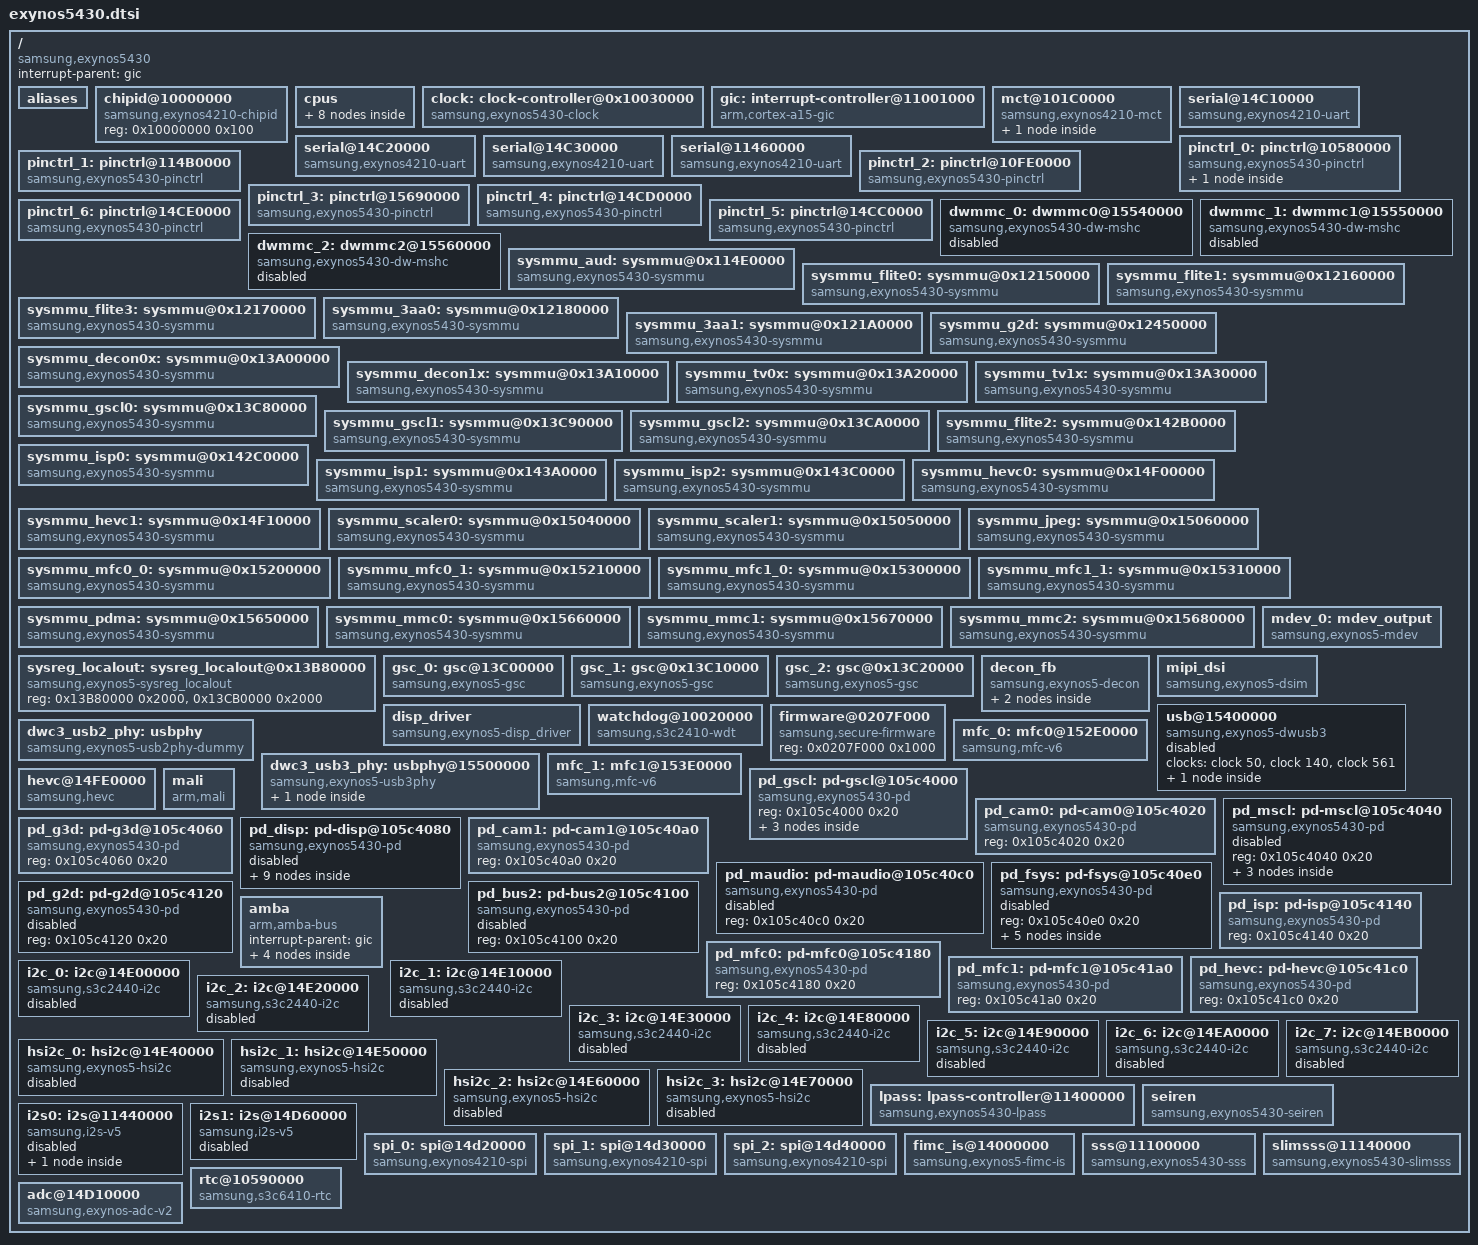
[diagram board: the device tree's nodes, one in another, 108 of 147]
/*
 * SAMSUNG EXYNOS5430 SoC device tree source
 *
 * Copyright (c) 2013 Samsung Electronics Co., Ltd.
 *		http://www.samsung.com
 *
 * SAMSUNG EXYNOS5430 SoC device nodes are listed in this file.
 * EXYNOS5430 based board files can include this file and provide
 * values for board specfic bindings.
 *
 * This program is free software; you can redistribute it and/or modify
 * it under the terms of the GNU General Public License version 2 as
 * published by the Free Software Foundation.
 */

#include "skeleton.dtsi"
/include/ "exynos5430-pinctrl.dtsi"
/ {
	compatible = "samsung,exynos5430";

	interrupt-parent = <&gic>;

	aliases {
		pinctrl0 = &pinctrl_0;
		pinctrl1 = &pinctrl_1;
		pinctrl2 = &pinctrl_2;
		pinctrl3 = &pinctrl_3;
		pinctrl4 = &pinctrl_4;
		pinctrl5 = &pinctrl_5;
		pinctrl6 = &pinctrl_6;
		mshc0 = &dwmmc_0;
		mshc1 = &dwmmc_1;
		mshc2 = &dwmmc_2;
		gsc0 = &gsc_0;
		gsc1 = &gsc_1;
		gsc2 = &gsc_2;
		mfc0 = &mfc_0;
		mfc1 = &mfc_1;
		mdev0 = &mdev_0;
		spi0 = &spi_0;
		spi1 = &spi_1;
		spi2 = &spi_2;
	};

	chipid@10000000 {
		compatible = "samsung,exynos4210-chipid";
		reg = <0x10000000 0x100>;
	};

	cpus {
		#address-cells = <1>;
		#size-cells = <0>;

		cpu@0 {
			device_type = "cpu";
			compatible = "arm,cortex-a7";
			reg = <0x100>;
		};
		cpu@1 {
			device_type = "cpu";
			compatible = "arm,cortex-a7";
			reg = <0x101>;
		};
		cpu@2 {
			device_type = "cpu";
			compatible = "arm,cortex-a7";
			reg = <0x102>;
		};
		cpu@3 {
			device_type = "cpu";
			compatible = "arm,cortex-a7";
			reg = <0x103>;
		};
		cpu@4 {
			device_type = "cpu";
			compatible = "arm,cortex-a15";
			reg = <0x0>;
		};
		cpu@5 {
			device_type = "cpu";
			compatible = "arm,cortex-a15";
			reg = <0x1>;
		};
		cpu@6 {
			device_type = "cpu";
			compatible = "arm,cortex-a15";
			reg = <0x2>;
		};
		cpu@7 {
			device_type = "cpu";
			compatible = "arm,cortex-a15";
			reg = <0x3>;
		};
	};

	clock: clock-controller@0x10030000 {
		compatible = "samsung,exynos5430-clock";
		reg = <0x10030000 0x1000>,
			<0x11800000 0x1000>,
			<0x11900000 0x1000>,
			<0x114C0000 0x1000>,
			<0x14800000 0x1000>,
			<0x13400000 0x1000>,
			<0x120D0000 0x1000>,
			<0x121C0000 0x1000>,
			<0x145D0000 0x1000>,
			<0x142F0000 0x1000>,
			<0x10FC0000 0x1000>,
			<0x13B90000 0x1000>,
			<0x156E0000 0x1000>,
			<0x12460000 0x1000>,
			<0x14AA0000 0x1000>,
			<0x13CF0000 0x1000>,
			<0x14F80000 0x1000>,
			<0x11060000 0x1000>,
			<0x146D0000 0x1000>,
			<0x14360000 0x1000>,
			<0x15280000 0x1000>,
			<0x15380000 0x1000>,
			<0x105B0000 0x1000>,
			<0x150D0000 0x1000>,
			<0x14C80000 0x1000>,
			<0x10040000 0x1000>;
		#clock-cells = <1>;
	};

	gic:interrupt-controller@11001000 {
		compatible = "arm,cortex-a15-gic";
		#interrupt-cells = <3>;
		interrupt-controller;
		reg =	<0x11001000 0x1000>,
			<0x11002000 0x1000>,
			<0x11004000 0x2000>,
			<0x11006000 0x2000>;
		interrupts = <1 9 0xf04>;
	};

	mct@101C0000 {
		compatible = "samsung,exynos4210-mct";
		reg = <0x101C0000 0x800>;
		interrupt-controller;
		#interrups-cells = <1>;
		interrupt-parent = <&mct_map>;
		interrupts =	<0>, <1>, <2>, <3>,
				<4>, <5>, <6>, <7>,
				<8>, <9>, <10>, <11>;
		clocks = <&clock 1>, <&clock 14>;
		clock-names = "fin_pll", "mct";

		mct_map: mct-map {
			#interrupt-cells = <1>;
			#address-cells = <0>;
			#size-cells = <0>;
			interrupt-map = <0 &gic 0 102 0>,
					<1 &gic 0 103 0>,
					<2 &gic 0 104 0>,
					<3 &gic 0 105 0>,
					<4 &gic 0 106 0>,
					<5 &gic 0 107 0>,
					<6 &gic 0 108 0>,
					<7 &gic 0 109 0>,
					<8 &gic 0 110 0>,
					<9 &gic 0 111 0>,
					<10 &gic 0 112 0>,
					<11 &gic 0 113 0>;
		};
	};

	serial@14C10000 {
		compatible = "samsung,exynos4210-uart";
		reg = <0x14C10000 0x100>;
		interrupts = <0 421 0>;
		pinctrl-names = "default";
		pinctrl-0 = <&uart0_bus>;
		clocks = <&clock 115>, <&clock 2437>;
		clock-names = "sclk_uart0", "gate_uart0";
	};

	serial@14C20000 {
		compatible = "samsung,exynos4210-uart";
		reg = <0x14C20000 0x100>;
		interrupts = <0 422 0>;
		pinctrl-names = "default";
		pinctrl-0 = <&uart1_bus>;
		clocks = <&clock 116>, <&clock 2436>;
		clock-names = "sclk_uart1", "gate_uart1";
	};

	serial@14C30000 {
		compatible = "samsung,exynos4210-uart";
		reg = <0x14C30000 0x100>;
		interrupts = <0 423 0>;
		pinctrl-names = "default";
		pinctrl-0 = <&uart2_bus>;
		clocks = <&clock 117>, <&clock 2435>;
		clock-names = "sclk_uart2", "gate_uart2";
	};

	serial@11460000 {
		compatible = "samsung,exynos4210-uart";
		reg = <0x11460000 0x100>;
		interrupts = <0 67 0>;
		pinctrl-names = "default";
		pinctrl-0 = <&uart_aud_bus>;
		clocks = <&clock 4156>, <&clock 2004>;
		clock-names = "sclk_uart3", "gate_uart3";
	};

	pinctrl_0: pinctrl@10580000 {
		compatible = "samsung,exynos5430-pinctrl";
		reg = <0x10580000 0x1000>;
		interrupts = <0 16 0>;

		wakeup-interrupt-controller {
			compatible = "samsung,exynos4210-wakeup-eint";
			interrupt-parent = <&gic>;
			interrupts = <0 16 0>;
		};
	};

	pinctrl_1: pinctrl@114B0000 {
		compatible = "samsung,exynos5430-pinctrl";
		reg = <0x114B0000 0x1000>;
		interrupts = <0 68 0>;
	};

	pinctrl_2: pinctrl@10FE0000 {
		compatible = "samsung,exynos5430-pinctrl";
		reg = <0x10FE0000 0x1000>;
		interrupts = <0 179 0>;
	};

	pinctrl_3: pinctrl@15690000 {
		compatible = "samsung,exynos5430-pinctrl";
		reg = <0x15690000 0x1000>;
		interrupts = <0 229 0>;
	};

	pinctrl_4: pinctrl@14CD0000 {
		compatible = "samsung,exynos5430-pinctrl";
		reg = <0x14CD0000 0x1100>;
		interrupts = <0 441 0>;
	};

	pinctrl_5: pinctrl@14CC0000 {
		compatible = "samsung,exynos5430-pinctrl";
		reg = <0x14CC0000 0x1100>;
		interrupts = <0 440 0>;
	};

	pinctrl_6: pinctrl@14CE0000 {
		compatible = "samsung,exynos5430-pinctrl";
		reg = <0x14CE0000 0x1100>;
		interrupts = <0 442 0>;
	};

	dwmmc_0: dwmmc0@15540000 {
		compatible = "samsung,exynos5430-dw-mshc";
		reg = <0x15540000 0x2000>;
		interrupts = <0 225 0>;
		#address-cells = <1>;
		#size-cells = <0>;
		clocks = <&clock 565>, <&clock 141>;
		clock-names = "biu", "ciu";
		status = "disabled";
	};

	dwmmc_1: dwmmc1@15550000 {
		compatible = "samsung,exynos5430-dw-mshc";
		reg = <0x15550000 0x2000>;
		interrupts = <0 226 0>;
		#address-cells = <1>;
		#size-cells = <0>;
		clocks = <&clock 566>, <&clock 142>;
		clock-names = "biu", "ciu";
		status = "disabled";
	};

	dwmmc_2: dwmmc2@15560000 {
		compatible = "samsung,exynos5430-dw-mshc";
		reg = <0x15560000 0x2000>;
		interrupts = <0 227 0>;
		#address-cells = <1>;
		#size-cells = <0>;
		clocks = <&clock 567>, <&clock 143>;
		clock-names = "biu", "ciu";
		status = "disabled";
	};

	sysmmu_aud: sysmmu@0x114E0000 {
		compatible = "samsung,exynos5430-sysmmu";
		reg = <0x114E0000 0x1000>;
		interrupts = <0 64 0>;
		status = "ok";
	};

	sysmmu_flite0: sysmmu@0x12150000 {
		compatible = "samsung,exynos5430-sysmmu";
		reg = <0x12150000 0x1000>;
		interrupts = <0 128 0>;
		samsung,power-domain = <&pd_cam0>;
		status = "ok";
	};

	sysmmu_flite1: sysmmu@0x12160000 {
		compatible = "samsung,exynos5430-sysmmu";
		reg = <0x12160000 0x1000>;
		interrupts = <0 130 0>;
		samsung,power-domain = <&pd_cam0>;
		status = "ok";
	};

	sysmmu_flite3: sysmmu@0x12170000 {
		compatible = "samsung,exynos5430-sysmmu";
		reg = <0x12170000 0x1000>;
		interrupts = <0 132 0>;
		samsung,power-domain = <&pd_cam0>;
		status = "ok";
	};

	sysmmu_3aa0: sysmmu@0x12180000 {
		compatible = "samsung,exynos5430-sysmmu";
		reg = <0x12180000 0x1000>;
		interrupts = <0 137 0>;
		samsung,power-domain = <&pd_cam0>;
		status = "ok";
	};

	sysmmu_3aa1: sysmmu@0x121A0000 {
		compatible = "samsung,exynos5430-sysmmu";
		reg = <0x121A0000 0x1000>;
		interrupts = <0 147 0>;
		samsung,power-domain = <&pd_cam0>;
		status = "ok";
	};

	sysmmu_g2d: sysmmu@0x12450000 {
		compatible = "samsung,exynos5430-sysmmu";
		reg = <0x12450000 0x1000>;
		interrupts = <0 257 0>;
		clock-names = "sysmmu", "master";
		clocks = <&clock 457>, <&clock 450>;
		status = "ok";
	};

	sysmmu_decon0x: sysmmu@0x13A00000 {
		compatible = "samsung,exynos5430-sysmmu";
		reg = <0x13A00000 0x1000>;
		interrupts = <0 192 0>;
		clock-names = "sysmmu", "master";
		clocks = <&clock 624>, <&clock 610>;
		status = "ok";
		samsung,power-domain = <&spd_decon>;
	};

	sysmmu_decon1x: sysmmu@0x13A10000 {
		compatible = "samsung,exynos5430-sysmmu";
		reg = <0x13A10000 0x1000>;
		interrupts = <0 194 0>;
		clock-names = "sysmmu", "master";
		clocks = <&clock 625>, <&clock 610>;
		status = "ok";
		samsung,power-domain = <&spd_decon>;
	};

	sysmmu_tv0x: sysmmu@0x13A20000 {
		compatible = "samsung,exynos5430-sysmmu";
		reg = <0x13A20000 0x1000>;
		interrupts = <0 214 0>;
		clock-names = "sysmmu", "master";
		clocks = <&clock 672>, <&clock 665>;
		status = "ok";
	};

	sysmmu_tv1x: sysmmu@0x13A30000 {
		compatible = "samsung,exynos5430-sysmmu";
		reg = <0x13A30000 0x1000>;
		interrupts = <0 216 0>;
		status = "ok";
	};

	sysmmu_gscl0: sysmmu@0x13C80000 {
		compatible = "samsung,exynos5430-sysmmu";
		reg = <0x13C80000 0x1000>;
		interrupts = <0 288 0>;
		clock-names = "sysmmu", "master";
		clocks = <&clock 490>, <&clock 480>;
		status = "ok";
		samsung,power-domain = <&spd_gscl0>;
	};

	sysmmu_gscl1: sysmmu@0x13C90000 {
		compatible = "samsung,exynos5430-sysmmu";
		reg = <0x13C90000 0x1000>;
		interrupts = <0 290 0>;
		clock-names = "sysmmu", "master";
		clocks = <&clock 491>, <&clock 481>;
		status = "ok";
		samsung,power-domain = <&spd_gscl1>;
	};

	sysmmu_gscl2: sysmmu@0x13CA0000 {
		compatible = "samsung,exynos5430-sysmmu";
		reg = <0x13CA0000 0x1000>;
		interrupts = <0 292 0>;
		clock-names = "sysmmu", "master";
		clocks = <&clock 492>, <&clock 482>;
		status = "ok";
		samsung,power-domain = <&spd_gscl2>;
	};

	sysmmu_flite2: sysmmu@0x142B0000 {
		compatible = "samsung,exynos5430-sysmmu";
		reg = <0x142B0000 0x1000>;
		interrupts = <0 160 0>;
		samsung,power-domain = <&pd_cam1>;
		status = "ok";
	};

	sysmmu_isp0: sysmmu@0x142C0000 {
		compatible = "samsung,exynos5430-sysmmu";
		reg = <0x142C0000 0x1000>,
		      <0x142D0000 0x1000>,
		      <0x14320000 0x1000>,
		      <0x14330000 0x1000>,
		      <0x14340000 0x1000>;
		interrupts = <0 162 0>,
			     <0 169 0>,
			     <0 346 0>,
			     <0 338 0>,
			     <0 340 0>;
		samsung,power-domain = <&pd_isp>;
		status = "ok";
	};

	sysmmu_isp1: sysmmu@0x143A0000 {
		compatible = "samsung,exynos5430-sysmmu";
		reg = <0x143A0000 0x1000>,
		      <0x143B0000 0x1000>,
		      <0x143D0000 0x1000>;
		interrupts = <0 342 0>,
			     <0 344 0>,
			     <0 349 0>;
		samsung,power-domain = <&pd_isp>;
		status = "ok";
	};

	sysmmu_isp2: sysmmu@0x143C0000 {
		compatible = "samsung,exynos5430-sysmmu";
		reg = <0x143C0000 0x1000>;
		interrupts = <0 336 0>;
		samsung,power-domain = <&pd_isp>;
		status = "ok";
	};

	sysmmu_hevc0: sysmmu@0x14F00000 {
		compatible = "samsung,exynos5430-sysmmu";
		reg = <0x14F00000 0x1000>;
		interrupts = <0 449 0>;
		clock-names = "sysmmu", "master";
		clocks = <&clock 745>, <&clock 740>;
		status = "ok";
	};

	sysmmu_hevc1: sysmmu@0x14F10000 {
		compatible = "samsung,exynos5430-sysmmu";
		reg = <0x14F10000 0x1000>;
		interrupts = <0 451 0>;
		clock-names = "sysmmu", "master";
		clocks = <&clock 746>, <&clock 740>;
		status = "ok";
	};


	sysmmu_scaler0: sysmmu@0x15040000 {
		compatible = "samsung,exynos5430-sysmmu";
		reg = <0x15040000 0x1000>;
		interrupts = <0 404 0>;
		clock-names = "sysmmu", "master";
		clocks = <&clock 530>, <&clock 520>;
		status = "ok";
	};

	sysmmu_scaler1: sysmmu@0x15050000 {
		compatible = "samsung,exynos5430-sysmmu";
		reg = <0x15050000 0x1000>;
		interrupts = <0 406 0>;
		clock-names = "sysmmu", "master";
		clocks = <&clock 531>, <&clock 521>;
		status = "ok";
	};

	sysmmu_jpeg: sysmmu@0x15060000 {
		compatible = "samsung,exynos5430-sysmmu";
		reg = <0x15060000 0x1000>;
		interrupts = <0 408 0>;
		clock-names = "sysmmu", "master";
		clocks = <&clock 532>, <&clock 522>;
		status = "ok";
	};

	sysmmu_mfc0_0: sysmmu@0x15200000 {
		compatible = "samsung,exynos5430-sysmmu";
		reg = <0x15200000 0x1000>;
		interrupts = <0 352 0>;
		clock-names = "sysmmu", "master";
		clocks = <&clock 685>, <&clock 680>;
		status = "ok";
	};

	sysmmu_mfc0_1: sysmmu@0x15210000 {
		compatible = "samsung,exynos5430-sysmmu";
		reg = <0x15210000 0x1000>;
		interrupts = <0 354 0>;
		clock-names = "sysmmu", "master";
		clocks = <&clock 686>, <&clock 680>;
		status = "ok";
	};


	sysmmu_mfc1_0: sysmmu@0x15300000 {
		compatible = "samsung,exynos5430-sysmmu";
		reg = <0x15300000 0x1000>;
		interrupts = <0 360 0>;
		clock-names = "sysmmu", "master";
		clocks = <&clock 715>, <&clock 710>;
		status = "ok";
	};

	sysmmu_mfc1_1: sysmmu@0x15310000 {
		compatible = "samsung,exynos5430-sysmmu";
		reg = <0x15310000 0x1000>;
		interrupts = <0 362 0>;
		clock-names = "sysmmu", "master";
		clocks = <&clock 716>, <&clock 710>;
		status = "ok";
	};

	sysmmu_pdma: sysmmu@0x15650000 {
		compatible = "samsung,exynos5430-sysmmu";
		reg = <0x15650000 0x1000>;
		interrupts = <0 240 0>;
		clock-names = "sysmmu", "master";
		clocks = <&clock 590>, <&clock 560>;
		status = "ok";
	};

	sysmmu_mmc0: sysmmu@0x15660000 {
		compatible = "samsung,exynos5430-sysmmu";
		reg = <0x15660000 0x1000>;
		interrupts = <0 233 0>;
		clock-names = "sysmmu", "master";
		clocks = <&clock 591>, <&clock 565>;
		status = "ok";
	};

	sysmmu_mmc1: sysmmu@0x15670000 {
		compatible = "samsung,exynos5430-sysmmu";
		reg = <0x15670000 0x1000>;
		interrupts = <0 236 0>;
		clock-names = "sysmmu", "master";
		clocks = <&clock 592>, <&clock 566>;
		status = "ok";
	};

	sysmmu_mmc2: sysmmu@0x15680000 {
		compatible = "samsung,exynos5430-sysmmu";
		reg = <0x15680000 0x1000>;
		interrupts = <0 238 0>;
		clock-names = "sysmmu", "master";
		clocks = <&clock 593>, <&clock 567>;
		status = "ok";
	};

	mdev_0: mdev_output {
		compatible = "samsung,exynos5-mdev";
	};

	sysreg_localout: sysreg_localout@0x13B80000 {
		compatible = "samsung,exynos5-sysreg_localout";
		reg = <0x13B80000 0x2000>, <0x13CB0000 0x2000>;
	};

	gsc_0: gsc@13C00000 {
		compatible = "samsung,exynos5-gsc";
		reg = <0x13C00000 0x1000>;
		interrupts = <0 297 0>;
		clocks = <&clock 2265>;
		clock-names = "gate_gscl";
		ip_ver = <2>;
		mif_min = <160000>;
		int_min = <111000>;
		iommu = <&sysmmu_gscl0>;
		samsung,power-domain = <&spd_gscl0>;
	};

	gsc_1: gsc@0x13C10000 {
		compatible = "samsung,exynos5-gsc";
		reg = <0x13C10000 0x1000>;
		interrupts = <0 298 0>;
		clocks = <&clock 2264>;
		clock-names = "gate_gscl";
		ip_ver = <2>;
		mif_min = <160000>;
		int_min = <111000>;
		iommu = <&sysmmu_gscl1>;
		samsung,power-domain = <&spd_gscl1>;
	};

	gsc_2: gsc@0x13C20000 {
		compatible = "samsung,exynos5-gsc";
		reg = <0x13C20000 0x1000>;
		interrupts = <0 299 0>;
		clocks = <&clock 2263>;
		clock-names = "gate_gscl";
		ip_ver = <2>;
		mif_min = <160000>;
		int_min = <111000>;
		iommu = <&sysmmu_gscl2>;
		samsung,power-domain = <&spd_gscl2>;
	};

	decon_fb: decon_fb {
		compatible = "samsung,exynos5-decon";
		reg = <0x13800000 0x40000>;
		samsung,vidcon0 = <0x00>;
		samsung,vidcon1 = <0x80>;
		samsung,default_win = <0>;

		samsung,i80_irq_no = <235>;
		samsung,irq_no = <234>;
		samsung,fifo_irq_no = <233>;

		gpios = <&gpf1 3 0xf>;
		clock-names = "mout_sclk_decon_eclk_a", "mout_bus_pll_sub", "mout_disp_pll",
			"aclk_disp_333", "aclk_disp_222", "sclk_decon_eclk_mif", "sclk_decon_vclk_mif", "sclk_dsd_mif",
			"mout_aclk_disp_333_user", "mout_aclk_disp_222_user", "mout_sclk_decon_eclk_user", "mout_sclk_decon_vclk_user", "mout_sclk_dsd_user",
			"mout_sclk_decon_eclk_disp",
			"dout_aclk_disp_333",
			"dout_sclk_decon_eclk";
		clocks = <&clock 3092>, <&clock 3075>, <&clock 3124>,
			 <&clock 321>, <&clock 322>, <&clock 81>, <&clock 82>, <&clock 83>,
			 <&clock 3125>, <&clock 3126>, <&clock 3130>, <&clock 3132>, <&clock 3134>,
			 <&clock 3131>,
			 <&clock 4116>,
			 <&clock 4122>;

		iommu = <&sysmmu_decon0x>, <&sysmmu_decon1x>;

		samsung,power-domain = <&spd_decon>;

		fb_driver_data {
			fb_variant {
				nr_windows = <5>;
				vidtcon = <0x2020>;
				wincon = <0x20>;
				winmap = <0x270>;
				keycon = <0x230>;
				osd = <0xB0>;
				osd_stride = <16>;
				buf_start = <0x150>;
				buf_size  = <0x200>;
				buf_end   = <0x1A0>;
				palette_0 = <0x2400>;
				palette_1 = <0x2800>;
				palette_2 = <0x2c00>;
				palette_3 = <0x3000>;
				palette_4 = <0x3400>;
				has_shadowcon = <1>;
				has_blendcon  = <1>;
				has_alphacon  = <1>;
				has_fixvclk   = <1>;
			};
		};
	};

	mipi_dsi: mipi_dsi {
		compatible = "samsung,exynos5-dsim";
		reg = <0x13900000 0x40000>;
		samsung,irq_no = <237>;

		clock-names = "phyclk_mipidphy_rxclkesc0_phy", "phyclk_mipidphy_bitclkdiv8_phy",
			"mout_phyclk_mipidphy_rxclkesc0_user", "mout_phyclk_mipidphy_bitclkdiv8_user";
		clocks = <&clock 5025>, <&clock 5026>,
			 <&clock 3137>, <&clock 3138>;

		pinctrl-names = "turnon_tes", "turnoff_tes";
		pinctrl-0 = <&disp_teson>;
		pinctrl-1 = <&disp_tesoff>;

		samsung,power-domain = <&spd_mipi_dsi>;
	};

	disp_driver {
		compatible = "samsung,exynos5-disp_driver";
	};

	watchdog@10020000 {
		compatible = "samsung,s3c2410-wdt";
		reg = <0x10020000 0x100>;
		interrupts = <0 101 0>;
		clocks = <&clock 870>;
		clock-names = "watchdog";
		timeout-sec = <30>;
		pmu_wdt_reset_type = <3>;
	};

	firmware@0207F000 {
		compatible = "samsung,secure-firmware";
		reg = <0x0207F000 0x1000>;
	};

	usb@15400000 {
		compatible = "samsung,exynos5-dwusb3";
		clocks = <&clock 50>, <&clock 140>, <&clock 561>;
		clock-names = "sclk_usbdrd30", "usbdrd30", "aclk_usbdrd30";
		#address-cells = <1>;
		#size-cells = <1>;
		ranges;
		status = "disabled";

		dwc3 {
			compatible = "synopsys,dwc3";
			reg = <0x15400000 0x10000>;
			interrupts = <0 231 0>;
			usb-phy = <&dwc3_usb2_phy &dwc3_usb3_phy>;
		};
	};

	dwc3_usb2_phy: usbphy {
		compatible = "samsung,exynos5-usb2phy-dummy";
	};

	dwc3_usb3_phy: usbphy@15500000 {
		compatible = "samsung,exynos5-usb3phy";
		reg = <0x15500000 0x100>;
		clocks = <&clock 1>, <&clock 140>, <&clock 410>, <&clock 411>;
		clock-names = "ext_xtal", "usbdrd30", "usbdrd30_phyclock", "usbdrd30_pipe_pclk";
		#address-cells = <1>;
		#size-cells = <1>;
		ranges;

		usbphy-sys {
			reg = <0x105C0704 0xC>;
		};
	};

	mfc_0: mfc0@152E0000 {
		compatible = "samsung,mfc-v6";
		reg = <0x152E0000 0x10000>;
		interrupts = <0 358 0>;
		clock-names = "gate_mfc0", "mout_aclk_mfc0_333_user", "aclk_mfc0_333", "mout_mfc_pll_user", "dout_mfc_pll", "mout_bus_pll_user", "dout_bus_pll";
		clocks = <&clock 2352>, <&clock 3121>, <&clock 332>, <&clock 3011>, <&clock 4102>, <&clock 3010>, <&clock 4101>;
		iommu = <&sysmmu_mfc0_0>, <&sysmmu_mfc0_1>;
		status = "ok";
		samsung,power-domain = <&pd_mfc0>;
	};

	mfc_1: mfc1@153E0000 {
		compatible = "samsung,mfc-v6";
		reg = <0x153E0000 0x10000>;
		interrupts = <0 366 0>;
		clock-names = "gate_mfc1", "mout_aclk_mfc1_333_user", "aclk_mfc1_333", "mout_mfc_pll_user", "dout_mfc_pll", "mout_bus_pll_user", "dout_bus_pll";
		clocks = <&clock 2372>, <&clock 3122>, <&clock 333>, <&clock 3011>, <&clock 4102>, <&clock 3010>, <&clock 4101>;
		iommu = <&sysmmu_mfc1_0>, <&sysmmu_mfc1_1>;
		samsung,power-domain = <&pd_mfc1>;
	};

	hevc@14FE0000 {
		compatible = "samsung,hevc";
		reg = <0x14FE0000 0x10000>;
		interrupts = <0 448 0>;
		clock-names = "gate_hevc", "mout_aclk_hevc_400_user", "aclk_hevc_400", "mout_mfc_pll_user", "dout_mfc_pll", "mout_bus_pll_user", "dout_bus_pll";
		clocks = <&clock 2292>, <&clock 3123>, <&clock 334>, <&clock 3011>, <&clock 4102>, <&clock 3010>, <&clock 4101>;
		iommu = <&sysmmu_hevc0>, <&sysmmu_hevc1>;
		status = "ok";
		samsung,power-domain = <&pd_hevc>;
	};

	mali {
		compatible = "arm,mali";
		reg = <0x14AC0000 0x5000>;
		interrupts = <0 282 0>, <0 283 0>, <0 281 0>;
		samsung,power-domain = <&pd_g3d>;
	};

	pd_gscl: pd-gscl@105c4000 {
		compatible = "samsung,exynos5430-pd";
		reg = <0x105c4000 0x20>;

		spd_gscl0: spd-gscl0@105c4000 {
			compatible = "samsung,exynos5430-spd";
		};

		spd_gscl1: spd-gscl1@105c4000 {
			compatible = "samsung,exynos5430-spd";
		};

		spd_gscl2: spd-gscl2@105c4000 {
			compatible = "samsung,exynos5430-spd";
		};
	};

	pd_cam0: pd-cam0@105c4020 {
		compatible = "samsung,exynos5430-pd";
		reg = <0x105c4020 0x20>;
	};

	pd_mscl: pd-mscl@105c4040 {
		compatible = "samsung,exynos5430-pd";
		reg = <0x105c4040 0x20>;
		status = "disabled";

		spd_mscl0: spd-mscl0@105c4040 {
			compatible = "samsung,exynos5430-spd";
		};

		spd_mscl1: spd-mscl1@105c4040 {
			compatible = "samsung,exynos5430-spd";
		};

		spd_jpeg: spd-jpeg@105c4040 {
			compatible = "samsung,exynos5430-spd";
		};
	};

	pd_g3d: pd-g3d@105c4060 {
		compatible = "samsung,exynos5430-pd";
		reg = <0x105c4060 0x20>;
	};

	pd_disp: pd-disp@105c4080 {
		compatible = "samsung,exynos5430-pd";
		reg = <0x105c4080 0x20>;
		pd-option = <0x0102>;
		status = "disabled";

		spd_decon: spd-decon@105c4080 {
			compatible = "samsung,exynos5430-spd";
		};

		spd_mipi_dsi: spd-mipi-dsi@105c4080 {
			compatible = "samsung,exynos5430-spd";
		};

		spd_mic: spd-mic@105c4080 {
			compatible = "samsung,exynos5430-spd";
		};

		spd_mdnie: spd-mdnie@105c4080 {
			compatible = "samsung,exynos5430-spd";
		};

		spd_decon_tv: spd-decon-tv@105c4080 {
			compatible = "samsung,exynos5430-spd";
		};

		spd_hdmi: spd-hdmi@105c4080 {
			compatible = "samsung,exynos5430-spd";
		};

		spd_hdmi_phy: spd-hdmi-phy@105c4080 {
			compatible = "samsung,exynos5430-spd";
		};

		spd_mipi_dphy_m4s4: spd-mipi-dphy-m4s4@105c4080 {
			compatible = "samsung,exynos5430-spd";
		};

		spd_pll_disp: spd-pll-disp@105c4080 {
			compatible = "samsung,exynos5430-spd";
		};
	};

	pd_cam1: pd-cam1@105c40a0 {
		compatible = "samsung,exynos5430-pd";
		reg = <0x105c40a0 0x20>;
	};

	pd_maudio: pd-maudio@105c40c0 {
		compatible = "samsung,exynos5430-pd";
		reg = <0x105c40c0 0x20>;
		status = "disabled";
	};

	pd_fsys: pd-fsys@105c40e0 {
		compatible = "samsung,exynos5430-pd";
		reg = <0x105c40e0 0x20>;
		status = "disabled";

		spd_usbhost20: spd-usbhost20@105c40e0 {
			compatible = "samsung,exynos5430-spd";
		};

		spd_usbdrd30: spd-usbdrd30@105c40e0 {
			compatible = "samsung,exynos5430-spd";
		};

		spd_dwmmc0: spd-dwmmc0@105c40e0 {
			compatible = "samsung,exynos5430-spd";
		};

		spd_dwmmc1: spd-dwmmc1@105c40e0 {
			compatible = "samsung,exynos5430-spd";
		};

		spd_dwmmc2: spd-dwmmc2@105c40e0 {
			compatible = "samsung,exynos5430-spd";
		};
	};

	pd_bus2: pd-bus2@105c4100 {
		compatible = "samsung,exynos5430-pd";
		reg = <0x105c4100 0x20>;
		status = "disabled";
	};

	pd_g2d: pd-g2d@105c4120 {
		compatible = "samsung,exynos5430-pd";
		reg = <0x105c4120 0x20>;
		status = "disabled";
	};

	pd_isp: pd-isp@105c4140 {
		compatible = "samsung,exynos5430-pd";
		reg = <0x105c4140 0x20>;
	};

	pd_mfc0: pd-mfc0@105c4180 {
		compatible = "samsung,exynos5430-pd";
		reg = <0x105c4180 0x20>;
	};

	pd_mfc1: pd-mfc1@105c41a0 {
		compatible = "samsung,exynos5430-pd";
		reg = <0x105c41a0 0x20>;
	};

	pd_hevc: pd-hevc@105c41c0 {
		compatible = "samsung,exynos5430-pd";
		reg = <0x105c41c0 0x20>;
	};

	amba {
		#address-cells = <1>;
		#size-cells = <1>;
		compatible = "arm,amba-bus";
		interrupt-parent = <&gic>;
		ranges;

		pdma: pdma@15610000 {
			compatible = "arm,pl330", "arm,primecell";
			reg = <0x15610000 0x1000>;
			interrupts = <0 228 0>;
			clocks = <&clock 590>, <&clock 560>;
			clock-names = "sysmmu", "apb_pclk";
			#dma-cells = <1>;
			#dma-channels = <8>;
			#dma-requests = <32>;
		};

		adma: adma@11420000 {
			compatible = "arm,pl330", "arm,primecell";
			reg = <0x11420000 0x1000>;
			interrupts = <0 73 0>;
			clocks = <&clock 771>;
			clock-names = "apb_pclk";
			#dma-cells = <1>;
			#dma-channels = <6>;
			#dma-requests = <16>;
		};

		mdma0: mdma@10F80000 {
			compatible = "arm,pl330", "arm,primecell";
			reg = <0x10F80000 0x1000>;
			interrupts = <0 182 0>;
			clocks = <&clock 1180>;
			clock-names = "apb_pclk";
			#dma-cells = <1>;
			#dma-channels = <2>;
			#dma-requests = <1>;
		};

		mdma1: mdma@12500000 {
			compatible = "arm,pl330", "arm,primecell";
			reg = <0x12500000 0x1000>;
			interrupts = <0 271 0>;
			clocks = <&clock 460>;
			clock-names = "apb_pclk";
			#dma-cells = <1>;
			#dma-channels = <4>;
			#dma-requests = <1>;
		};
	};

	i2c_0: i2c@14E00000 {
		compatible = "samsung,s3c2440-i2c";
		reg = <0x14E00000 0x1000>;
		interrupts = <0 424 0>;
		#address-cells = <1>;
		#size-cells = <0>;
		pinctrl-names = "default";
		pinctrl-0 = <&i2c0_bus>;
		clocks = <&clock 893>;
		clock-names = "i2c";
		status = "disabled";
	};

	i2c_1: i2c@14E10000 {
		compatible = "samsung,s3c2440-i2c";
		reg = <0x14E10000 0x1000>;
		interrupts = <0 425 0>;
		#address-cells = <1>;
		#size-cells = <0>;
		pinctrl-names = "default";
		pinctrl-0 = <&i2c1_bus>;
		clocks = <&clock 894>;
		clock-names = "i2c";
		status = "disabled";
	};

	i2c_2: i2c@14E20000 {
		compatible = "samsung,s3c2440-i2c";
		reg = <0x14E20000 0x1000>;
		interrupts = <0 426 0>;
		#address-cells = <1>;
		#size-cells = <0>;
		pinctrl-names = "default";
		pinctrl-0 = <&i2c2_bus>;
		clocks = <&clock 895>;
		clock-names = "i2c";
		status = "disabled";
	};

	i2c_3: i2c@14E30000 {
		compatible = "samsung,s3c2440-i2c";
		reg = <0x14E30000 0x1000>;
		interrupts = <0 427 0>;
		#address-cells = <1>;
		#size-cells = <0>;
		pinctrl-names = "default";
		pinctrl-0 = <&i2c3_bus>;
		clocks = <&clock 896>;
		clock-names = "i2c";
		status = "disabled";
	};

	i2c_4: i2c@14E80000 {
		compatible = "samsung,s3c2440-i2c";
		reg = <0x14E80000 0x1000>;
		interrupts = <0 443 0>;
		#address-cells = <1>;
		#size-cells = <0>;
		pinctrl-names = "default";
		pinctrl-0 = <&i2c4_bus>;
		clocks = <&clock 897>;
		clock-names = "i2c";
		status = "disabled";
	};

	i2c_5: i2c@14E90000 {
		compatible = "samsung,s3c2440-i2c";
		reg = <0x14E90000 0x1000>;
		interrupts = <0 444 0>;
		#address-cells = <1>;
		#size-cells = <0>;
		pinctrl-names = "default";
		pinctrl-0 = <&i2c5_bus>;
		clocks = <&clock 898>;
		clock-names = "i2c";
		status = "disabled";
	};

	i2c_6: i2c@14EA0000 {
		compatible = "samsung,s3c2440-i2c";
		reg = <0x14EA0000 0x1000>;
		interrupts = <0 445 0>;
		#address-cells = <1>;
		#size-cells = <0>;
		pinctrl-names = "default";
		pinctrl-0 = <&i2c6_bus>;
		clocks = <&clock 899>;
		clock-names = "i2c";
		status = "disabled";
	};

	i2c_7: i2c@14EB0000 {
		compatible = "samsung,s3c2440-i2c";
		reg = <0x14EB0000 0x1000>;
		interrupts = <0 446 0>;
		#address-cells = <1>;
		#size-cells = <0>;
		pinctrl-names = "default";
		pinctrl-0 = <&i2c7_bus>;
		clocks = <&clock 900>;
		clock-names = "i2c";
		status = "disabled";
	};

	hsi2c_0: hsi2c@14E40000 {
		compatible = "samsung,exynos5-hsi2c";
		reg = <0x14E40000 0x1000>;
		interrupts = <0 428 0>;
		#address-cells = <1>;
		#size-cells = <0>;
		pinctrl-names = "default";
		pinctrl-0 = <&hs_i2c0_bus>;
		clocks = <&clock 901>;
		clock-names = "hsi2c";
		status = "disabled";
	};

	hsi2c_1: hsi2c@14E50000 {
		compatible = "samsung,exynos5-hsi2c";
		reg = <0x14E50000 0x1000>;
		interrupts = <0 429 0>;
		#address-cells = <1>;
		#size-cells = <0>;
		pinctrl-names = "default";
		pinctrl-0 = <&hs_i2c1_bus>;
		clocks = <&clock 902>;
		clock-names = "hsi2c";
		status = "disabled";
	};

	hsi2c_2: hsi2c@14E60000 {
		compatible = "samsung,exynos5-hsi2c";
		reg = <0x14E60000 0x1000>;
		interrupts = <0 430 0>;
		#address-cells = <1>;
		#size-cells = <0>;
		pinctrl-names = "default";
		pinctrl-0 = <&hs_i2c2_bus>;
		clocks = <&clock 903>;
		clock-names = "hsi2c";
		status = "disabled";
	};

	hsi2c_3: hsi2c@14E70000 {
		compatible = "samsung,exynos5-hsi2c";
		reg = <0x14E70000 0x1000>;
		interrupts = <0 431 0>;
		#address-cells = <1>;
		#size-cells = <0>;
		pinctrl-names = "default";
		pinctrl-0 = <&hs_i2c3_bus>;
		clocks = <&clock 903>;
		clock-names = "hsi2c";
		status = "disabled";
	};

	lpass: lpass-controller@11400000 {
		compatible = "samsung,exynos5430-lpass";
		reg = <0x11400000 0x100>,
		      <0x03000000 0x48000>;
		clocks = <&clock 771>,
			 <&clock 772>,
			 <&clock 779>,
			 <&clock 780>,
			 <&clock 785>,
			 <&clock 786>,
			 <&clock 787>,
			 <&clock 788>;
		clock-names = "dmac", "sramc", "intr", "timer",
			      "sysreg", "pmu", "gpio", "dbg";
		status = "ok";
	};

	seiren {
		compatible = "samsung,exynos5430-seiren";
		interrupts = <0 69 0>;
		clocks = <&clock 770>;
		clock-names = "ca5";
		status = "ok";
	};

	i2s0: i2s@11440000 {
		compatible = "samsung,i2s-v5";
		reg = <0x11440000 0x100>;
		dmas = <&adma 0 &adma 2>;
		dma-names = "tx", "rx";
		interrupts = <0 70 0>;
		clocks = <&clock 781>,		/* pclk_i2s */
			 <&clock 781>,		/* pclk_i2s */
			 <&clock 789>;		/* sclk_i2s */
		clock-names = "iis", "i2s_opclk0", "i2s_opclk1";
		samsung,supports-6ch;
		samsung,supports-rstclr;
		samsung,supports-secdai;
		samsung,supports-tdm;
		samsung,supports-low-rfs;
		pinctrl-names = "default";
		pinctrl-0 = <&i2s0_bus>;
		status = "disabled";
		i2s-sec {
			dmas = <&adma 1>;
			dma-names = "tx-sec";
		};
	};

	i2s1: i2s@14D60000 {
		compatible = "samsung,i2s-v5";
		reg = <0x14D60000 0x100>;
		dmas = <&pdma 31 &pdma 30>;
		dma-names = "tx", "rx";
		interrupts = <0 435 0>;
		clocks = <&clock 914>,		/* pclk_i2s1 */
			 <&clock 914>,		/* pclk_i2s1 */
			 <&clock 111>;		/* sclk_i2s1 */
		clock-names = "iis", "i2s_opclk0", "i2s_opclk1";
		samsung,supports-6ch;
		samsung,supports-rstclr;
		samsung,supports-tdm;
		pinctrl-names = "default";
		pinctrl-0 = <&i2s1_bus>;
		status = "disabled";
	};

	spi_0: spi@14d20000 {
		compatible = "samsung,exynos4210-spi";
		reg = <0x14d20000 0x100>;
		interrupts = <0 432 0>;
		dma-mode;
		dmas = <&pdma 9
			&pdma 8>;
		dma-names = "tx", "rx";
		swap-mode;
		#address-cells = <1>;
		#size-cells = <0>;
		clocks = <&clock 2427>, <&clock 4057>;
		clock-names = "spi", "spi_busclk0";
		pinctrl-names = "default";
		pinctrl-0 = <&spi0_bus>;
	};

	spi_1: spi@14d30000 {
		compatible = "samsung,exynos4210-spi";
		reg = <0x14d30000 0x100>;
		interrupts = <0 433 0>;
		dma-mode;
		dmas = <&pdma 11
			&pdma 10>;
		dma-names = "tx", "rx";
		swap-mode;
		#address-cells = <1>;
		#size-cells = <0>;
		clocks = <&clock 2426>, <&clock 4058>;
		clock-names = "spi", "spi_busclk0";
		pinctrl-names = "default";
		pinctrl-0 = <&spi1_bus>;
	};

	spi_2: spi@14d40000 {
		compatible = "samsung,exynos4210-spi";
		reg = <0x14d40000 0x100>;
		interrupts = <0 434 0>;
		dma-mode;
		dmas = <&pdma 13
			&pdma 12>;
		dma-names = "tx", "rx";
		swap-mode;
		#address-cells = <1>;
		#size-cells = <0>;
		clocks = <&clock 2425>, <&clock 4059>;
		clock-names = "spi", "spi_busclk0";
		pinctrl-names = "default";
		pinctrl-0 = <&spi2_bus>;
	};

	fimc_is@14000000 {
		compatible = "samsung,exynos5-fimc-is";
		reg = <0x14000000 0x1A0000>;
		interrupts = <0 165 0>, /* ARMISP_GIC */
			     <0 166 0>; /* ISP_GIC */
		pinctrl-names = "fimc-is-uart",
				"main-i2c",
				"main-mclk",
				"vt-i2c",
				"vt-mclk",
				"fimc-is-spi0";
		pinctrl-0 = <&fimc_is_uart>;
		pinctrl-1 = <&fimc_is_main_i2c>;
		pinctrl-2 = <&fimc_is_main_mclk>;
		pinctrl-3 = <&fimc_is_vt_i2c>;
		pinctrl-4 = <&fimc_is_vt_mclk>;
		pinctrl-5 = <&fimc_is_spi0>;
		clocks = <&clock 33>, <&clock 34>, <&clock 35>;
		clock-names =	"sclk_isp_sensor0",
				"sclk_isp_sensor1",
				"sclk_isp_sensor2";
		gpios =	<&gpc0 1 0x1 /* MAINCAM_RESET */
			&gpc2 0 0x2 /* MAINCAM_SDA_1.8V */
			&gpc2 1 0x2 /* MAINCAM_SCL_1.8V */
			&gpd7 0 0x2 /* MAINCAM_MCLK(CIS_CLK0) */
			&gpc0 2 0x1 /* CAM_FLASH_EN */
			&gpc0 3 0x1 /* CAM_FLASH_TORCH */
			&gpc0 4 0x1 /* VTCAM_RESET */
			&gpc2 2 0x2 /* VTCAM_SDA_1.8V */
			&gpc2 3 0x2 /* VTCAM_SCL_1.8V */
			&gpd7 1 0x2 /* VTCAM_MCLK(CIS_CLK1) */
			&gpc3 0 0x2 /* MAINCAM_SPI_CLK */
			&gpc3 1 0x2 /* MAINCAM_SPI_CSN */
			&gpc3 2 0x2 /* MAINCAM_SPI_MISO */
			&gpc3 3 0x2 /* MAINCAM_SPI_MOSI */
			&gpc0 7 0x3 /* ISP_UART_TXD */
			&gpc1 1 0x3>; /* ISP_UART_RXD */
		iommu = <&sysmmu_flite0>,
			<&sysmmu_flite1>,
			<&sysmmu_flite2>,
			<&sysmmu_flite3>,
			<&sysmmu_3aa0>,
			<&sysmmu_3aa1>,
			<&sysmmu_isp0>,
			<&sysmmu_isp1>,
			<&sysmmu_isp2>;
		samsung,power-domain = <&pd_cam0
					&pd_cam1
					&pd_isp>;
		status = "ok";
	};

	sss@11100000 {
		compatible = "samsung,exynos5430-sss";
		reg = <0x11100000 0x8000>;
		interrupts = <0 315 0>;
		clocks = <&clock 2334>;
		clock-names = "secss";
	};

	slimsss@11140000 {
		compatible = "samsung,exynos5430-slimsss";
		reg = <0x11140000 0x1000>;
		interrupts = <0 312 0>;
		clocks = <&clock 2335>;
		clock-names = "slimsss";
	};

	rtc@10590000 {
		compatible = "samsung,s3c6410-rtc";
		reg = <0x10590000 0x100>;
		interrupts = <0 385 0>, <0 386 0>;
		clocks = <&clock 1041>;
		clock-names = "rtc";
	};

	adc@14D10000 {
		compatible = "samsung,exynos-adc-v2";
		reg = <0x14D10000 0x100>;
		interrupts = <0 438 0>;
		#io-channel-cells = <1>;
		io-channel-ranges;
		clocks = <&clock 2428>;
		clock-names = "gate_adcif";
	};
};
